# ATSAMG54N19 device description
Architecture: CORTEX-M4; Family: SAMG; Series: SAMG54
Registers are 32-bit, read-write, no defined reset value unless marked. A register's access mark holds for its fields unless they carry their own. Offsets are from the block's base; [hi:lo] are bit positions; {n}, {i} and the like mark numbered series; 'fields as' and 'values as' point back to an identical list.

## ADC — Analog-to-Digital Converter
Instances: ADC 0x40038000
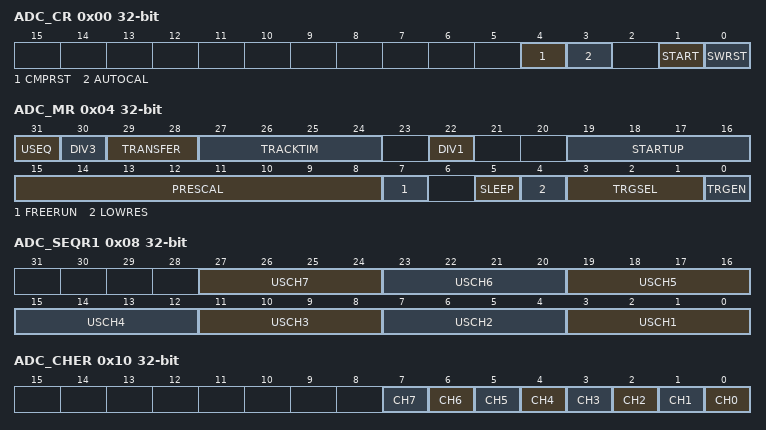
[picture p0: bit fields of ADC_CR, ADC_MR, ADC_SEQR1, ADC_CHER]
0x00 ADC_CR wo — Control Register
  [4] CMPRST — Comparison Restart
  [3] AUTOCAL — Automatic Calibration of ADC
  [1] START — Start Conversion
  [0] SWRST — Software Reset
0x04 ADC_MR — Mode Register
  [31] USEQ — Use Sequence Enable
    0=NUM_ORDER (Normal Mode: The controller converts channels in a simple numeric order depending only on the channel index.); 1=REG_ORDER (User Sequence Mode: The sequence respects what is defined in ADC_SEQR1 register and can be used to convert the same channel several times.)
  [30] DIV3 — ADC Clock Prescaler Division forced to 3
    0=NO_DIV3 (The PRESCAL field is used to generate the ADC clock unless DIV1 is written to 1.); 1=FORCE_DIV3 (The ADC clock equals peripheral clock/3 unless DIV1 is written to 1.)
  [29:28] TRANSFER — Transfer Period
  [27:24] TRACKTIM — Tracking Time
  [22] DIV1 — ADC Clock Prescaler Division forced to 1
    0=NO_DIV1 (The PRESCAL field is used to generate the ADC clock unless DIV3 is written to 1.); 1=FORCE_DIV1 (The ADC clock equals peripheral clock (PRESCAL and DIV3 fields have no effect).)
  [19:16] STARTUP — Start Up Time
    0=SUT0 (0 periods of ADCCLK); 1=SUT8 (8 periods of ADCCLK); 2=SUT16 (16 periods of ADCCLK); 3=SUT24 (24 periods of ADCCLK); 4=SUT64 (64 periods of ADCCLK); 5=SUT80 (80 periods of ADCCLK); 6=SUT96 (96 periods of ADCCLK); 7=SUT112 (112 periods of ADCCLK); 8=SUT512 (512 periods of ADCCLK); 9=SUT576 (576 periods of ADCCLK); 10=SUT640 (640 periods of ADCCLK); 11=SUT704 (704 periods of ADCCLK); 12=SUT768 (768 periods of ADCCLK); 13=SUT832 (832 periods of ADCCLK); 14=SUT896 (896 periods of ADCCLK); 15=SUT960 (960 periods of ADCCLK)
  [15:8] PRESCAL — Prescaler Rate Selection
  [7] FREERUN — Free Run Mode
    0=OFF (Normal Mode); 1=ON (Free Run Mode: Never wait for any trigger.)
  [5] SLEEP — Sleep Mode
    0=NORMAL (Normal Mode: The ADC core and reference voltage circuitry are kept ON between conversions.); 1=SLEEP (Sleep Mode: The ADC core and reference voltage circuitry are OFF between conversions.)
  [4] LOWRES — Resolution
    0=BITS_10 (10-bit resolution. For higher resolution by averaging, please refer to "ADC Extended Mode Register" on page 77.); 1=BITS_8 (8-bit resolution)
  [3:1] TRGSEL — Trigger Selection
    0=ADC_TRIG0 (External trigger); 1=ADC_TRIG1 (TIO Output of the Timer Counter Channel 0); 2=ADC_TRIG2 (TIO Output of the Timer Counter Channel 1); 3=ADC_TRIG3 (TIO Output of the Timer Counter Channel 2); 4=ADC_TRIG4 (RTCOUT0); 5=ADC_TRIG5 (RTTINC)
  [0] TRGEN — Trigger Enable
    0=DIS (Hardware triggers are disabled. Starting a conversion is only possible by software.); 1=EN (Hardware trigger selected by TRGSEL field is enabled.)
0x08 ADC_SEQR1 — Channel Sequence Register 1
  [4n-1:4n-4] USCH{n} (n=1..7) — User Sequence Number {n}
0x10 ADC_CHER wo (atomic set of ADC_CHSR) — Channel Enable Register
  [n] CH{n} (n=0..7) — Channel {n} Enable
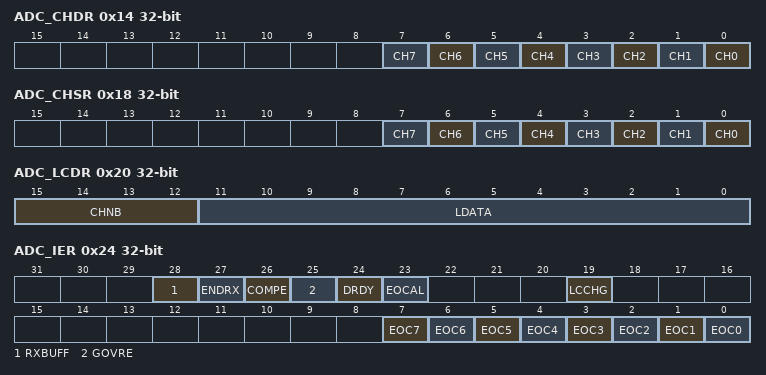
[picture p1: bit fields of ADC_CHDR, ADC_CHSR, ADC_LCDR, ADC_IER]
0x14 ADC_CHDR wo (atomic clear of ADC_CHSR) — Channel Disable Register
  [n] CH{n} (n=0..7) — Channel {n} Disable
0x18 ADC_CHSR ro — Channel Status Register
  [n] CH{n} (n=0..7) — Channel {n} Status
0x20 ADC_LCDR ro — Last Converted Data Register
  [15:12] CHNB — Channel Number
  [11:0] LDATA — Last Data Converted
0x24 ADC_IER wo (atomic set of ADC_IMR) — Interrupt Enable Register
  [28] RXBUFF — Receive Buffer Full Interrupt Enable
  [27] ENDRX — End of Receive Buffer Interrupt Enable
  [26] COMPE — Comparison Event Interrupt Enable
  [25] GOVRE — General Overrun Error Interrupt Enable
  [24] DRDY — Data Ready Interrupt Enable
  [23] EOCAL — End of Calibration Sequence
  [19] LCCHG — Last Channel Change Interrupt Enable
  [n] EOC{n} (n=0..7) — End of Conversion Interrupt Enable {n}
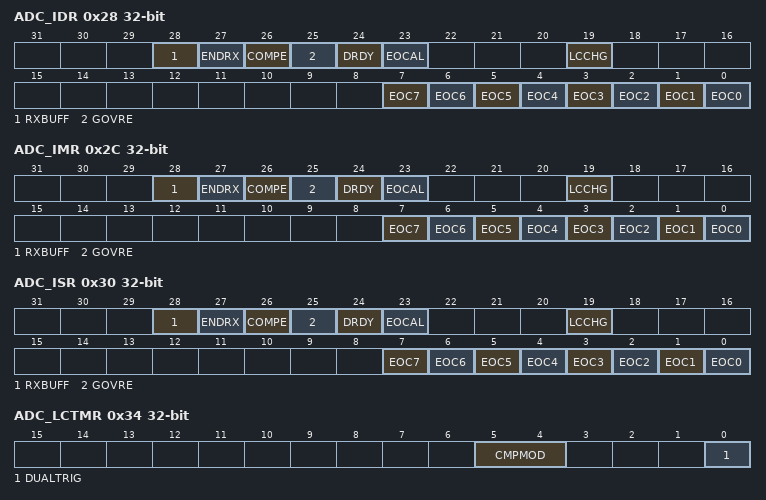
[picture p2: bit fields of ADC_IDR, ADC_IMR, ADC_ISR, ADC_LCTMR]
0x28 ADC_IDR wo (atomic clear of ADC_IMR) — Interrupt Disable Register
  [28] RXBUFF — Receive Buffer Full Interrupt Disable
  [27] ENDRX — End of Receive Buffer Interrupt Disable
  [26] COMPE — Comparison Event Interrupt Disable
  [25] GOVRE — General Overrun Error Interrupt Disable
  [24] DRDY — Data Ready Interrupt Disable
  [23] EOCAL — End of Calibration Sequence
  [19] LCCHG — Last Channel Change Interrupt Disable
  [n] EOC{n} (n=0..7) — End of Conversion Interrupt Disable {n}
0x2C ADC_IMR ro (atomic read) — Interrupt Mask Register
  [28] RXBUFF — Receive Buffer Full Interrupt Mask
  [27] ENDRX — End of Receive Buffer Interrupt Mask
  [26] COMPE — Comparison Event Interrupt Mask
  [25] GOVRE — General Overrun Error Interrupt Mask
  [24] DRDY — Data Ready Interrupt Mask
  [23] EOCAL — End of Calibration Sequence
  [19] LCCHG — Last Channel Change Interrupt Mask
  [n] EOC{n} (n=0..7) — End of Conversion Interrupt Mask {n}
0x30 ADC_ISR ro (atomic read) — Interrupt Status Register
  [28] RXBUFF — Receive Buffer Full (cleared by writing ADC_RCR or ADC_RNCR)
  [27] ENDRX — End of Receive Transfer (cleared by writing ADC_RCR or ADC_RNCR)
  [26] COMPE — Comparison Event (cleared on read)
  [25] GOVRE — General Overrun Error (cleared on read)
  [24] DRDY — Data Ready (automatically set / cleared)
  [23] EOCAL — End of Calibration Sequence
  [19] LCCHG — Last Channel Change (cleared on read)
  [n] EOC{n} (n=0..7) — End of Conversion {n} (automatically set / cleared)
0x34 ADC_LCTMR — Last Channel Trigger Mode Register
  [5:4] CMPMOD — Last Channel Comparison Mode
    0=LOW (Generates an event when the converted data is lower than the low threshold of the window.); 1=HIGH (Generates an event when the converted data is higher than the high threshold of the window.); 2=IN (Generates an event when the converted data is in the comparison window.); 3=OUT (Generates an event when the converted data is out of the comparison window.)
  [0] DUALTRIG — Dual Trigger ON
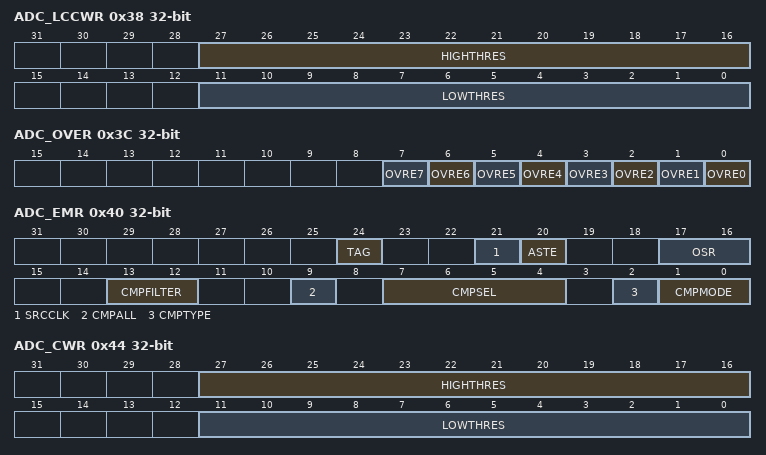
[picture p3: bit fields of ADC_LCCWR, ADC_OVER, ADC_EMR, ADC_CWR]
0x38 ADC_LCCWR — Last Channel Compare Window Register
  [27:16] HIGHTHRES — High Threshold
  [11:0] LOWTHRES — Low Threshold
0x3C ADC_OVER ro — Overrun Status Register
  [n] OVRE{n} (n=0..7) — Overrun Error {n}
0x40 ADC_EMR — Extended Mode Register
  [24] TAG — Tag of the ADC_LCDR
  [21] SRCCLK — External Clock Selection
    0=PERIPH_CLK (The peripheral clock is the source for the ADC prescaler.); 1=PMC_PCK (PMC PCKx is the source clock for the ADC prescaler, thus the ADC clock can be independent of the core/peripheral clock.)
  [20] ASTE — Averaging on Single Trigger Event
    0=MULTI_TRIG_AVERAGE (The average requests several trigger events.); 1=SINGLE_TRIG_AVERAGE (The average requests only one trigger event.)
  [17:16] OSR — Over Sampling Rate
    0=NO_AVERAGE (No averaging. ADC sample rate is maximum.); 1=1-bit enhanced resolution by averaging. ADC sample rate divided by 4.; 2=2-bit enhanced resolution by averaging. ADC sample rate divided by 16.
  [13:12] CMPFILTER — Compare Event Filtering
  [9] CMPALL — Compare All Channels
  [7:4] CMPSEL — Comparison Selected Channel
  [2] CMPTYPE — Comparison Type
    0=FLAG_ONLY (Any conversion is performed and comparison function drives the COMPE flag.); 1=START_CONDITION (Comparison conditions must be met to start the storage of all conversions until the CMPRST bit is set.)
  [1:0] CMPMODE — Comparison Mode
    values as ADC_LCTMR.CMPMOD
0x44 ADC_CWR — Compare Window Register
  [27:16] HIGHTHRES — High Threshold
  [11:0] LOWTHRES — Low Threshold
{0x50+4i} ADC_CDR[{i}] (i=0..7) ro — Channel Data Register 0
  [11:0] DATA — Converted Data
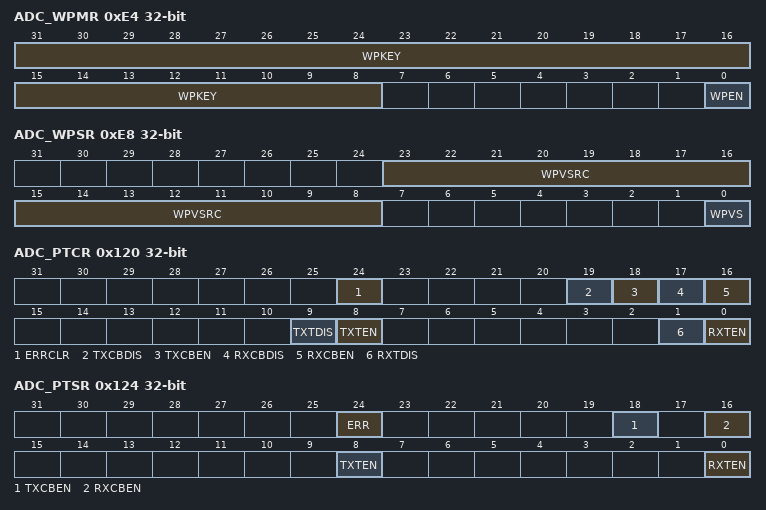
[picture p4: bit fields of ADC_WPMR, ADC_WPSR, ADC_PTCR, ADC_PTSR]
0xE4 ADC_WPMR — Write Protection Mode Register
  [31:8] WPKEY — Write Protection Key
    0x414443=PASSWD (Writing any other value in this field aborts the write operation of the WPEN bit.Always reads as 0)
  [0] WPEN — Write Protection Enable
0xE8 ADC_WPSR ro — Write Protection Status Register
  [23:8] WPVSRC — Write Protection Violation Source
  [0] WPVS — Write Protection Violation Status
0x100 ADC_RPR — Receive Pointer Register
  [31:0] RXPTR
0x104 ADC_RCR — Receive Counter Register
  [15:0] RXCTR
0x110 ADC_RNPR — Receive Next Pointer Register
  [31:0] RXNPTR — Receive Next Pointer
0x114 ADC_RNCR — Receive Next Counter Register
  [15:0] RXNCTR — Receive Next Counter
0x120 ADC_PTCR wo — Transfer Control Register
  [24] ERRCLR — Transfer Bus Error Clear
  [19] TXCBDIS — Transmitter Circular Buffer Disable
  [18] TXCBEN — Transmitter Circular Buffer Enable
  [17] RXCBDIS — Receiver Circular Buffer Disable
  [16] RXCBEN — Receiver Circular Buffer Enable
  [9] TXTDIS — Transmitter Transfer Disable
  [8] TXTEN — Transmitter Transfer Enable
  [1] RXTDIS — Receiver Transfer Disable
  [0] RXTEN — Receiver Transfer Enable
0x124 ADC_PTSR ro — Transfer Status Register
  [24] ERR — Transfer Bus Error
  [18] TXCBEN — Transmitter Circular Buffer Enable
  [16] RXCBEN — Receiver Circular Buffer Enable
  [8] TXTEN — Transmitter Transfer Enable
  [0] RXTEN — Receiver Transfer Enable

## Notices in the file
Copyright (c) 2017 Microchip Technology Inc.
SPDX-License-Identifier: Apache-2.0
Licensed under the Apache License, Version 2.0 (the "License");
you may not use this file except in compliance with the License.
You may obtain a copy of the License at
http://www.apache.org/licenses/LICENSE-2.0
Unless required by applicable law or agreed to in writing, software
distributed under the License is distributed on an "AS IS" BASIS,
WITHOUT WARRANTIES OR CONDITIONS OF ANY KIND, either express or implied.
See the License for the specific language governing permissions and
limitations under the License.
